# MSP430F5529 register map
Vendor: msp430gen; File version: VERGEN_IDEMPOTENT_OUTPUT
Registers are 8-bit, read-write, reset 0x0 unless marked. A register's access mark holds for its fields unless they carry their own. Offsets are from the block's base; [hi:lo] are bit positions; {n}, {i} and the like mark numbered series.

## USCI_B1_I2C_MODE
Base 0x00000620
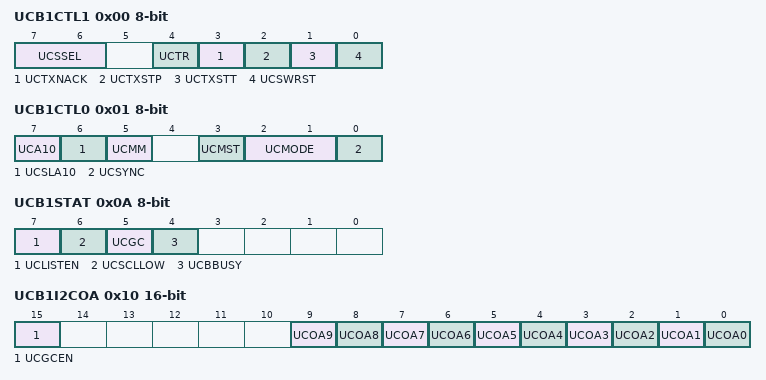
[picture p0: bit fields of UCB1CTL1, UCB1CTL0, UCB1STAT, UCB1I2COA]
0x00 UCB1CTL1 — USCI B1 Control Register 1
  [7:6] UCSSEL — USCI 1 Clock Source Select 1
    {v}=USCI 0 Clock Source: {v} (v=0..3)
  [4] UCTR — Transmit/Receive Select/Flag
  [3] UCTXNACK — Transmit NACK
  [2] UCTXSTP — Transmit STOP
  [1] UCTXSTT — Transmit START
  [0] UCSWRST — USCI Software Reset
0x01 UCB1CTL0 — USCI B1 Control Register 0
  [7] UCA10 — 10-bit Address Mode
  [6] UCSLA10 — 10-bit Slave Address Mode
  [5] UCMM — Multi-Master Environment
  [3] UCMST — Sync. Mode: Master Select
  [2:1] UCMODE — Sync. Mode: USCI Mode 1
    {v}=Sync. Mode: USCI Mode: {v} (v=0..3)
  [0] UCSYNC — Sync-Mode 0:UART-Mode / 1:SPI-Mode
0x06 UCB1BR0 — USCI B1 Baud Rate 0
0x07 UCB1BR1 — USCI B1 Baud Rate 1
0x0A UCB1STAT — USCI B1 Status Register
  [7] UCLISTEN — USCI Listen mode
  [6] UCSCLLOW — SCL low
  [5] UCGC — General Call address received Flag
  [4] UCBBUSY — Bus Busy Flag
0x0C UCB1RXBUF — USCI B1 Receive Buffer
0x0E UCB1TXBUF — USCI B1 Transmit Buffer
0x10 UCB1I2COA 16-bit — USCI B1 I2C Own Address
  [15] UCGCEN — I2C General Call enable
  [n] UCOA{n} (n=0..9) — I2C Own Address {n}
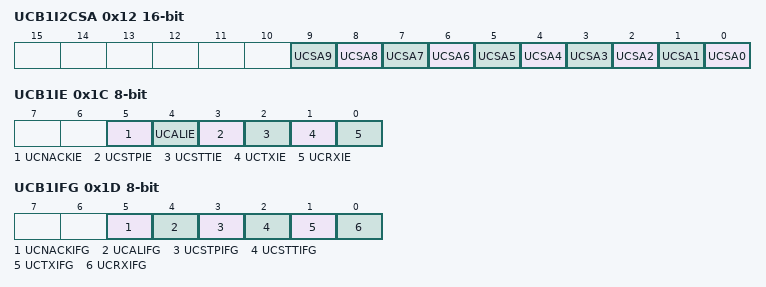
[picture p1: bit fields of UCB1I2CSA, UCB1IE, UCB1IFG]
0x12 UCB1I2CSA 16-bit — USCI B1 I2C Slave Address
  [n] UCSA{n} (n=0..9) — I2C Slave Address {n}
0x1C UCB1IE — USCI B1 Interrupt Enable Register
  [5] UCNACKIE — NACK Condition interrupt enable
  [4] UCALIE — Arbitration Lost interrupt enable
  [3] UCSTPIE — STOP Condition interrupt enable
  [2] UCSTTIE — START Condition interrupt enable
  [1] UCTXIE — USCI Transmit Interrupt Enable
  [0] UCRXIE — USCI Receive Interrupt Enable
0x1D UCB1IFG — USCI B1 Interrupt Flags Register
  [5] UCNACKIFG — NAK Condition interrupt Flag
  [4] UCALIFG — Arbitration Lost interrupt Flag
  [3] UCSTPIFG — STOP Condition interrupt Flag
  [2] UCSTTIFG — START Condition interrupt Flag
  [1] UCTXIFG — USCI Transmit Interrupt Flag
  [0] UCRXIFG — USCI Receive Interrupt Flag
0x1E UCB1IV 16-bit — USCI B1 Interrupt Vector Register

## USCI_B1_SPI_MODE
Base 0x00000620
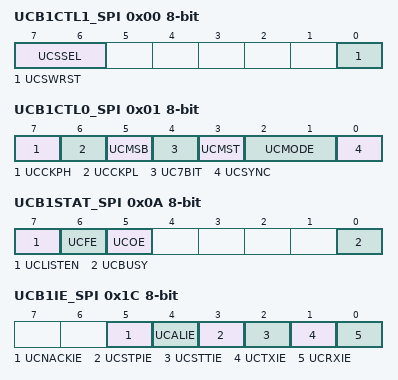
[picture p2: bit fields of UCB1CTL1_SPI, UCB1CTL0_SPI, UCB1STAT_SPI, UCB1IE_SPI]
0x00 UCB1CTL1_SPI — USCI B1 Control Register 1
  [7:6] UCSSEL — USCI 1 Clock Source Select 1
    {v}=USCI 0 Clock Source: {v} (v=0..3)
  [0] UCSWRST — USCI Software Reset
0x01 UCB1CTL0_SPI — USCI B1 Control Register 0
  [7] UCCKPH — Sync. Mode: Clock Phase
  [6] UCCKPL — Sync. Mode: Clock Polarity
  [5] UCMSB — Sync. Mode: MSB first 0:LSB / 1:MSB
  [4] UC7BIT — Sync. Mode: Data Bits 0:8-bits / 1:7-bits
  [3] UCMST — Sync. Mode: Master Select
  [2:1] UCMODE — Sync. Mode: USCI Mode 1
    {v}=Sync. Mode: USCI Mode: {v} (v=0..3)
  [0] UCSYNC — Sync-Mode 0:UART-Mode / 1:SPI-Mode
0x06 UCB1BR0_SPI — USCI B1 Baud Rate 0
0x07 UCB1BR1_SPI — USCI B1 Baud Rate 1
0x0A UCB1STAT_SPI — USCI B1 Status Register
  [7] UCLISTEN — USCI Listen mode
  [6] UCFE — USCI Frame Error Flag
  [5] UCOE — USCI Overrun Error Flag
  [0] UCBUSY — USCI Busy Flag
0x0C UCB1RXBUF_SPI — USCI B1 Receive Buffer
0x0E UCB1TXBUF_SPI — USCI B1 Transmit Buffer
0x1C UCB1IE_SPI — USCI B1 Interrupt Enable Register
  [5] UCNACKIE — NACK Condition interrupt enable
  [4] UCALIE — Arbitration Lost interrupt enable
  [3] UCSTPIE — STOP Condition interrupt enable
  [2] UCSTTIE — START Condition interrupt enable
  [1] UCTXIE — USCI Transmit Interrupt Enable
  [0] UCRXIE — USCI Receive Interrupt Enable
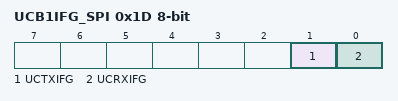
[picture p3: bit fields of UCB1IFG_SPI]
0x1D UCB1IFG_SPI — USCI B1 Interrupt Flags Register
  [1] UCTXIFG — USCI Transmit Interrupt Flag
  [0] UCRXIFG — USCI Receive Interrupt Flag
0x1E UCB1IV_SPI 16-bit — USCI B1 Interrupt Vector Register

## ADC12
Base 0x00000700
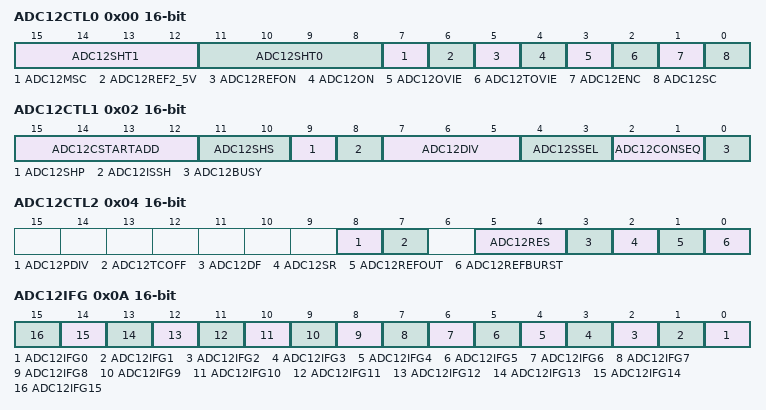
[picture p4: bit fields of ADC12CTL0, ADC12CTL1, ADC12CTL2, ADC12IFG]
0x00 ADC12CTL0 16-bit — ADC12+ Control 0
  [15:12] ADC12SHT1 — ADC12 Sample Hold 1 Select Bit: 0
    {v}=ADC12 Sample Hold 1 Select Bit: {v} (v=0..15)
  [11:8] ADC12SHT0 — ADC12 Sample Hold 0 Select Bit: 0
    {v}=ADC12 Sample Hold 0 Select Bit: {v} (v=0..15)
  [7] ADC12MSC — ADC12 Multiple SampleConversion
  [6] ADC12REF2_5V — ADC12 Ref 0:1.5V / 1:2.5V
  [5] ADC12REFON — ADC12 Reference on
  [4] ADC12ON — ADC12 On/enable
  [3] ADC12OVIE — ADC12 Overflow interrupt enable
  [2] ADC12TOVIE — ADC12 Timer Overflow interrupt enable
  [1] ADC12ENC — ADC12 Enable Conversion
  [0] ADC12SC — ADC12 Start Conversion
0x02 ADC12CTL1 16-bit — ADC12+ Control 1
  [15:12] ADC12CSTARTADD — ADC12 Conversion Start Address Bit: 0
    {v}=ADC12 Conversion Start Address: {v} (v=0..15)
  [11:10] ADC12SHS — ADC12 Sample/Hold Source Bit: 0
    {v}=ADC12 Sample/Hold Source: {v} (v=0..3)
  [9] ADC12SHP — ADC12 Sample/Hold Pulse Mode
  [8] ADC12ISSH — ADC12 Invert Sample Hold Signal
  [7:5] ADC12DIV — ADC12 Clock Divider Select Bit: 0
    {v}=ADC12 Clock Divider Select: {v} (v=0..7)
  [4:3] ADC12SSEL — ADC12 Clock Source Select Bit: 0
    {v}=ADC12 Clock Source Select: {v} (v=0..3)
  [2:1] ADC12CONSEQ — ADC12 Conversion Sequence Select Bit: 0
    {v}=ADC12 Conversion Sequence Select: {v} (v=0..3)
  [0] ADC12BUSY
0x04 ADC12CTL2 16-bit — ADC12+ Control 2
  [8] ADC12PDIV — ADC12+ predivider 0:/1 1:/4
  [7] ADC12TCOFF — ADC12+ Temperature Sensor Off
  [5:4] ADC12RES — ADC12+ Resolution Bit: 0
    0=ADC12+ Resolution : 8 Bit; 1=ADC12+ Resolution : 10 Bit; 2=ADC12+ Resolution : 12 Bit; 3=ADC12+ Resolution : reserved
  [3] ADC12DF — ADC12+ Data Format
  [2] ADC12SR — ADC12+ Sampling Rate
  [1] ADC12REFOUT — ADC12+ Reference Out
  [0] ADC12REFBURST — ADC12+ Reference Burst
0x0A ADC12IFG 16-bit — ADC12+ Interrupt Flag
  [n] ADC12IFG{n} (n=0..15) — ADC12 Memory {n} Interrupt Flag
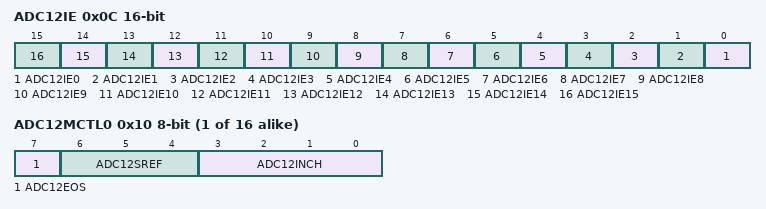
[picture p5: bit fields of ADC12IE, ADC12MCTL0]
0x0C ADC12IE 16-bit — ADC12+ Interrupt Enable
  [n] ADC12IE{n} (n=0..15) — ADC12 Memory {n} Interrupt Enable
0x0E ADC12IV 16-bit — ADC12+ Interrupt Vector Word
{0x10+i} ADC12MCTL{i} (i=0..15) — ADC12 Memory Control {i}
  [7] ADC12EOS — ADC12 End of Sequence
  [6:4] ADC12SREF — ADC12 Select Reference Bit 0
    {v}=ADC12 Select Reference {v} (v=0..7)
  [3:0] ADC12INCH — ADC12 Input Channel Select Bit 0
    {v}=ADC12 Input Channel {v} (v=0..15)
{0x20+2i} ADC12MEM{i} 16-bit (i=0..15) — ADC12 Conversion Memory {i}
